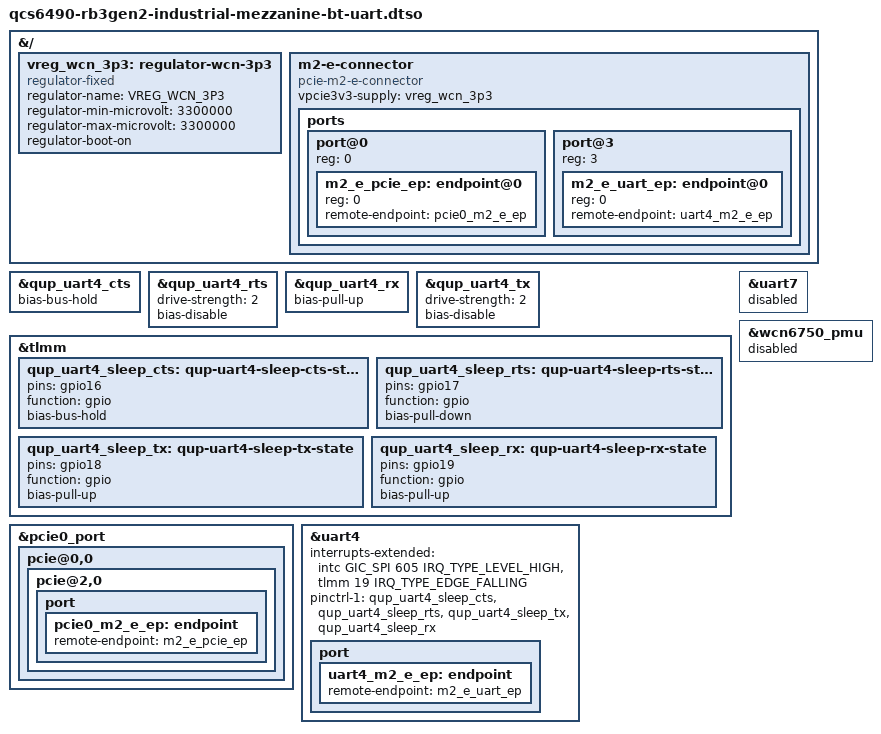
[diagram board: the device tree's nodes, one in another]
// SPDX-License-Identifier: BSD-3-Clause
/*
 * Copyright (c) 2026 Qualcomm Innovation Center, Inc. All rights reserved.
 */

/dts-v1/;
/plugin/;

#include <dt-bindings/gpio/gpio.h>
#include <dt-bindings/interrupt-controller/arm-gic.h>

&{/} {
	vreg_wcn_3p3: regulator-wcn-3p3 {
		compatible = "regulator-fixed";
		regulator-name = "VREG_WCN_3P3";
		regulator-min-microvolt = <3300000>;
		regulator-max-microvolt = <3300000>;

		regulator-boot-on;
	};

	m2-e-connector {
		compatible = "pcie-m2-e-connector";
		vpcie3v3-supply = <&vreg_wcn_3p3>;

		ports {
			#address-cells = <1>;
			#size-cells = <0>;

			port@0 {
				reg = <0>;
				#address-cells = <1>;
				#size-cells = <0>;

				m2_e_pcie_ep: endpoint@0 {
					reg = <0>;
					remote-endpoint = <&pcie0_m2_e_ep>;
				};
			};

			port@3 {
				reg = <3>;
				#address-cells = <1>;
				#size-cells = <0>;

				m2_e_uart_ep: endpoint@0 {
					reg = <0>;
					remote-endpoint = <&uart4_m2_e_ep>;
				};
			};
		};
	};
};

&qup_uart4_cts {
	bias-bus-hold;
};

&qup_uart4_rts {
	drive-strength = <2>;
	bias-disable;
};

&qup_uart4_rx {
	bias-pull-up;
};

&qup_uart4_tx {
	drive-strength = <2>;
	bias-disable;
};

&tlmm {
	qup_uart4_sleep_cts: qup-uart4-sleep-cts-state {
		pins = "gpio16";
		function = "gpio";
		bias-bus-hold;
	};

	qup_uart4_sleep_rts: qup-uart4-sleep-rts-state {
		pins = "gpio17";
		function = "gpio";
		bias-pull-down;
	};

	qup_uart4_sleep_tx: qup-uart4-sleep-tx-state {
		pins = "gpio18";
		function = "gpio";
		bias-pull-up;
	};

	qup_uart4_sleep_rx: qup-uart4-sleep-rx-state {
		pins = "gpio19";
		function = "gpio";
		bias-pull-up;
	};
};

&pcie0_port {
	pcie@0,0 {
		pcie@2,0 {
			port {
				pcie0_m2_e_ep: endpoint {
					remote-endpoint = <&m2_e_pcie_ep>;
				};
			};
		};
	};
};

&uart4 {
	interrupts-extended = <&intc GIC_SPI 605 IRQ_TYPE_LEVEL_HIGH>,
			      <&tlmm 19 IRQ_TYPE_EDGE_FALLING>;
	pinctrl-names = "default", "sleep";
	pinctrl-1 = <&qup_uart4_sleep_cts>, <&qup_uart4_sleep_rts>,
		    <&qup_uart4_sleep_tx>, <&qup_uart4_sleep_rx>;

	status = "okay";

	port {
		uart4_m2_e_ep: endpoint {
			remote-endpoint = <&m2_e_uart_ep>;
		};
	};
};

&uart7 {
	status = "disabled";
};

&wcn6750_pmu {
	status = "disabled";
};
